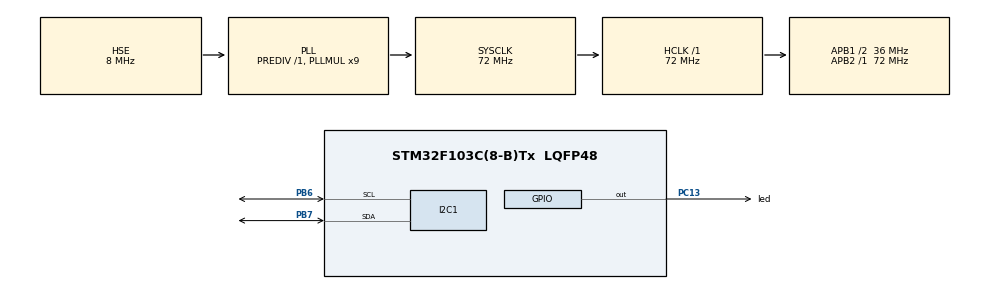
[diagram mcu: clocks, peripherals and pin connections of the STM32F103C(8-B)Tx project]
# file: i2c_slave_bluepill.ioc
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Mcu.Family=STM32F1
RCC.PLLSourceVirtual=RCC_PLLSOURCE_HSE
PD1-OSC_OUT.Mode=HSE-External-Oscillator
NVIC.I2C1_EV_IRQn=true\:5\:0\:true\:false\:true\:true\:true
PC13-TAMPER-RTC.Signal=GPIO_Output
PD0-OSC_IN.Signal=RCC_OSC_IN
RCC.APB1CLKDivider=RCC_HCLK_DIV2
RCC.SYSCLKSource=RCC_SYSCLKSOURCE_PLLCLK
ProjectManager.StackSize=0x400
PD1-OSC_OUT.Signal=RCC_OSC_OUT
PA13.Signal=SYS_JTMS-SWDIO
ProjectManager.TargetToolchain=STM32CubeIDE
RCC.HCLKFreq_Value=72000000
RCC.APB2TimFreq_Value=72000000
PB6.Signal=I2C1_SCL
PB6.Mode=I2C
RCC.USBFreq_Value=72000000
RCC.AHBFreq_Value=72000000
PD0-OSC_IN.Mode=HSE-External-Oscillator
board=custom
RCC.PLLMUL=RCC_PLL_MUL9
PC13-TAMPER-RTC.GPIO_Label=led
RCC.APB2Freq_Value=72000000
PA14.Mode=Serial_Wire
NVIC.TIM2_IRQn=true\:0\:0\:false\:false\:true\:false\:true
PB7.Signal=I2C1_SDA
PA13.Mode=Serial_Wire
NVIC.I2C1_ER_IRQn=true\:5\:0\:true\:false\:true\:true\:true
Mcu.Name=STM32F103C(8-B)Tx
I2C1.OwnAddress=0x15
RCC.SYSCLKFreq_VALUE=72000000
Mcu.Package=LQFP48
VP_SYS_VS_tim2.Mode=TIM2
NVIC.TimeBase=TIM2_IRQn
PB7.Mode=I2C
NVIC.TimeBaseIP=TIM2
PA14.Signal=SYS_JTCK-SWCLK
ProjectManager.HeapSize=0x200
NVIC.PriorityGroup=NVIC_PRIORITYGROUP_4
RCC.APB1TimFreq_Value=72000000
RCC.APB1Freq_Value=36000000

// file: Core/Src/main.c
/* USER CODE BEGIN Header */
/**
  ******************************************************************************
  * @file           : main.c
  * @brief          : Main program body
  ******************************************************************************
  * @attention
  *
  * <h2><center>&copy; Copyright (c) 2024 STMicroelectronics.
  * All rights reserved.</center></h2>
  *
  * This software component is licensed by ST under BSD 3-Clause license,
  * the "License"; You may not use this file except in compliance with the
  * License. You may obtain a copy of the License at:
  *                        opensource.org/licenses/BSD-3-Clause
  *
  ******************************************************************************
  */
/* USER CODE END Header */
#include "main.h"

/* USER CODE BEGIN Includes */
#include "FreeRTOS.h"
#include "task.h"
#include "queue.h"
#include "semphr.h"
#include <stdio.h>
#include <stdlib.h>
#include <string.h>
#include "i2c_slave_bluepill.h"
/* USER CODE END Includes */

/* USER CODE BEGIN PTD */
typedef struct{
	uint8_t value, meaning;
}queueData_t;
/* USER CODE END PTD */

/* USER CODE BEGIN PD */
#define blinkTASK_STACK_SIZE  	configMINIMAL_STACK_SIZE
#define blinkTASK_PRIORITY		tskIDLE_PRIORITY + 1

#define sendTASK_STACK_SIZE  	configMINIMAL_STACK_SIZE
#define sendTASK_PRIORITY		tskIDLE_PRIORITY + 1

#define defBUFFER_SIZE 128
#define commandBIT 1

#define runRTOS 'A'
#define LED_ON 'B'
#define LED_OFF 'C'
#define resp 'D'
#define MSG "Hola12\n"

#define MSG2 "123456789012345678901234567890123456789012345678901234567890\n"
#define MSG3 "01,r,1,xxxx1111,0,5,$"
#define MSGOK "00,l,x,xxxxxxx1,x,5,$"
#define MSGNO "00,l,x,xxxxxxx1,x,4,$"
#define MSGDEN "01,r,x,xxxx1110,x,6,$"
#define MSGA "02,a,1,5,$"
/* USER CODE END PD */

I2C_HandleTypeDef hi2c1;

/* USER CODE BEGIN PV */
TaskHandle_t hi2c_task, hblk_task, snd_task;
QueueHandle_t hi2c_q, hblk_q, send_q;

uint8_t flag_rtos = RESET;

uint8_t counter = 0;
/* USER CODE END PV */

void SystemClock_Config(void);
static void MX_GPIO_Init(void);
static void MX_I2C1_Init(void);
/* USER CODE BEGIN PFP */
void i2c_slave_rx_process(uint8_t* data, uint16_t size) {
	queueData_t queueData;
	BaseType_t hptw = SET;
	uint16_t value;
	char test[defBUFFER_SIZE];
	char p,q,r;

	memset(&test,'\0', sizeof(test));

	/*value = (uint16_t) atoi((char*) &data[commandBIT]);

	i2c_set_txBuffer(MSG3, strlen(MSG3));
	 */

	strcpy(test, data);

	p = data[3];

	if(p=='l'){
		q = test[18];
		value = (uint16_t) atoi((char*) test[18]);
		if (q == '2') {//SCAN
			if(counter==0){
				i2c_set_txBuffer(MSGNO, strlen(MSGNO));//responde que no hay informacion
			}
			else{
				i2c_set_txBuffer(MSGOK, strlen(MSGOK));//responde que hay informacion
			}

		} else if (q == '0') {//solicitud de informacion
			switch (counter){
							case 0:
								i2c_set_txBuffer(MSGNO, strlen(MSGNO));//responde que no hay informacion
								break;

							case 1:
								i2c_set_txBuffer(MSG3, strlen(MSG3));//responde mensaje 1: acceso de usuario
								counter--;
								break;
							case 2:
								i2c_set_txBuffer(MSGA, strlen(MSGA));//responde mensaje 2: actuador
								counter--;
								break;

			}
			//i2c_set_txBuffer(MSG3, strlen(MSG3));//responde que hay informacion
		}
	}
	if(p=='p'){
		q = test[18];
		//value = (uint16_t) atoi((char*) test[18]);
		if (q == '0') {//solisitud de accseo
			r = test[14];
			if(r == '1'){
				i2c_set_txBuffer(MSG3, strlen(MSG3));//responde acceso ok

			}
			else{
				i2c_set_txBuffer(MSGDEN, strlen(MSGDEN));//responde acceso den
			}

			counter = 2;
		}
	}

	//i2c_set_txBuffer(MSG3, strlen(MSG3));

	//flag_rtos = SET;
	/*
	if(!flag_rtos) {
		if(runRTOS == data[0]) {
			flag_rtos = SET;
			return;
		}
		else
			return;

	}
	switch(data[0]) {
	case LED_ON:
		queueData.value = RESET;
		xQueueSendFromISR(hblk_q, &queueData, &hptw);
		break;

	case LED_OFF:
		queueData.value = SET;
		xQueueSendFromISR(hblk_q, &queueData, &hptw);
		break;

	case resp:

		if (counter < 254){
			counter++;
		}
		else{
			counter = 0;
		}
		queueData.value = counter;
		xQueueSendFromISR(send_q, &queueData, &hptw);
		break;

	default: break;

	}
	*/
}

static void blinkTask(void *pvParameters) {
	//vTaskSuspend(NULL); //Task Jumper
	queueData_t queueData;

	for(;;) {
		xQueueReceive(hblk_q, &queueData, portMAX_DELAY);
		HAL_GPIO_WritePin(led_GPIO_Port, led_Pin, queueData.value);
	}
}

static void sndTask(void *pvParameters) {
	//vTaskSuspend(NULL); //Task Jumper
	queueData_t queueData;
	//uint8_t valor;
	char test[6];
	for(;;) {
		xQueueReceive(send_q, &queueData, portMAX_DELAY);
		//valor = queueData.value;

		memset(&test,'\0', sizeof(test));
		//itoa(queueData.value, test, 10);
		//strcat(test, MSG3);
		i2c_set_txBuffer(&test, strlen(test));
		//i2c_set_txBuffer((uint8_t *)MSG2, strlen(MSG2));
		/*
		if (counter < 254){
			counter++;
		}
		else{
			counter = 0;
		}
		*/
		//vTaskDelay(1000/portTICK_PERIOD_MS);
	}
}

static void startRTOS() {
	HAL_GPIO_WritePin(led_GPIO_Port, led_Pin, SET);
	i2c_set_txBuffer((uint8_t *) MSG3, strlen(MSG3));

	hi2c_q = xQueueCreate(1, sizeof(queueData_t));
	hblk_q = xQueueCreate(1, sizeof(queueData_t));
	send_q = xQueueCreate(1, sizeof(queueData_t));

	xTaskCreate(blinkTask,
			"LED PC13 blink Task",
			blinkTASK_STACK_SIZE,
			NULL,
			blinkTASK_PRIORITY,
			&hblk_task);
	xTaskCreate(sndTask,
			"send Task",
			sendTASK_STACK_SIZE,
			NULL,
			sendTASK_PRIORITY,
			&snd_task);

	vTaskStartScheduler();
}

static void bareMetalProcess() {
	for(;;) {
		HAL_GPIO_TogglePin(led_GPIO_Port, led_Pin);
		HAL_Delay(100);
		if(flag_rtos)
			startRTOS();
	}
}
/* USER CODE END PFP */

int main(void)
{

  /* MCU Configuration--------------------------------------------------------*/

  /* Reset of all peripherals, Initializes the Flash interface and the Systick. */

	HAL_Init();

  /* Configure the system clock */
  SystemClock_Config();

  /* Initialize all configured peripherals */
  MX_GPIO_Init();
  MX_I2C1_Init();
  /* USER CODE BEGIN 2 */
  i2c_start_listen_check(&hi2c1);
  bareMetalProcess();
  /* USER CODE END 2 */

  /* Infinite loop */
  while (1)
  {

  }
}

void SystemClock_Config(void)
{
  RCC_OscInitTypeDef RCC_OscInitStruct = {0};
  RCC_ClkInitTypeDef RCC_ClkInitStruct = {0};

  /** Initializes the RCC Oscillators according to the specified parameters
  * in the RCC_OscInitTypeDef structure.
  */
  RCC_OscInitStruct.OscillatorType = RCC_OSCILLATORTYPE_HSE;
  RCC_OscInitStruct.HSEState = RCC_HSE_ON;
  RCC_OscInitStruct.HSEPredivValue = RCC_HSE_PREDIV_DIV1;
  RCC_OscInitStruct.HSIState = RCC_HSI_ON;
  RCC_OscInitStruct.PLL.PLLState = RCC_PLL_ON;
  RCC_OscInitStruct.PLL.PLLSource = RCC_PLLSOURCE_HSE;
  RCC_OscInitStruct.PLL.PLLMUL = RCC_PLL_MUL9;
  if (HAL_RCC_OscConfig(&RCC_OscInitStruct) != HAL_OK)
  {
    Error_Handler();
  }
  /** Initializes the CPU, AHB and APB buses clocks
  */
  RCC_ClkInitStruct.ClockType = RCC_CLOCKTYPE_HCLK|RCC_CLOCKTYPE_SYSCLK
                              |RCC_CLOCKTYPE_PCLK1|RCC_CLOCKTYPE_PCLK2;
  RCC_ClkInitStruct.SYSCLKSource = RCC_SYSCLKSOURCE_PLLCLK;
  RCC_ClkInitStruct.AHBCLKDivider = RCC_SYSCLK_DIV1;
  RCC_ClkInitStruct.APB1CLKDivider = RCC_HCLK_DIV2;
  RCC_ClkInitStruct.APB2CLKDivider = RCC_HCLK_DIV1;

  if (HAL_RCC_ClockConfig(&RCC_ClkInitStruct, FLASH_LATENCY_2) != HAL_OK)
  {
    Error_Handler();
  }
}

static void MX_I2C1_Init(void)
{

  hi2c1.Instance = I2C1;
  hi2c1.Init.ClockSpeed = 100000;
  hi2c1.Init.DutyCycle = I2C_DUTYCYCLE_2;
  hi2c1.Init.OwnAddress1 = 42;
  hi2c1.Init.AddressingMode = I2C_ADDRESSINGMODE_7BIT;
  hi2c1.Init.DualAddressMode = I2C_DUALADDRESS_DISABLE;
  hi2c1.Init.OwnAddress2 = 0;
  hi2c1.Init.GeneralCallMode = I2C_GENERALCALL_DISABLE;
  hi2c1.Init.NoStretchMode = I2C_NOSTRETCH_DISABLE;
  if (HAL_I2C_Init(&hi2c1) != HAL_OK)
  {
    Error_Handler();
  }

}

static void MX_GPIO_Init(void)
{
  GPIO_InitTypeDef GPIO_InitStruct = {0};

  /* GPIO Ports Clock Enable */
  __HAL_RCC_GPIOC_CLK_ENABLE();
  __HAL_RCC_GPIOD_CLK_ENABLE();
  __HAL_RCC_GPIOA_CLK_ENABLE();
  __HAL_RCC_GPIOB_CLK_ENABLE();

  /*Configure GPIO pin Output Level */
  HAL_GPIO_WritePin(led_GPIO_Port, led_Pin, GPIO_PIN_RESET);

  /*Configure GPIO pin : led_Pin */
  GPIO_InitStruct.Pin = led_Pin;
  GPIO_InitStruct.Mode = GPIO_MODE_OUTPUT_PP;
  GPIO_InitStruct.Pull = GPIO_NOPULL;
  GPIO_InitStruct.Speed = GPIO_SPEED_FREQ_LOW;
  HAL_GPIO_Init(led_GPIO_Port, &GPIO_InitStruct);

}

 /**
  * @brief  Period elapsed callback in non blocking mode
  * @note   This function is called  when TIM2 interrupt took place, inside
  * HAL_TIM_IRQHandler(). It makes a direct call to HAL_IncTick() to increment
  * a global variable "uwTick" used as application time base.
  * @param  htim : TIM handle
  * @retval None
  */
void HAL_TIM_PeriodElapsedCallback(TIM_HandleTypeDef *htim)
{
  if (htim->Instance == TIM2) {
    HAL_IncTick();
  }
}

void Error_Handler(void)
{
  __disable_irq();
  while (1)
  {
  }
}

/************************ (C) COPYRIGHT STMicroelectronics *****END OF FILE****/
